# ATSAMA5D35 register map
Vendor: Microchip Technology; Series: SAMA5D3; File version: 0
Registers are 32-bit, read-write, reset 0x0 unless marked. A register's access mark holds for its fields unless they carry their own. Offsets are from the block's base; [hi:lo] are bit positions; lines under a group give offsets from that group; {n}, {i} and the like mark numbered series; 'fields as' and 'values as' point back to an identical list.

## TC0 — Timer Counter
Base 0xF0010000; register names take the prefix TC_
Same registers: TC1 0xF8014000
{0x0+0x40*i} TC_CHANNEL[{i}] (i=0..2) group
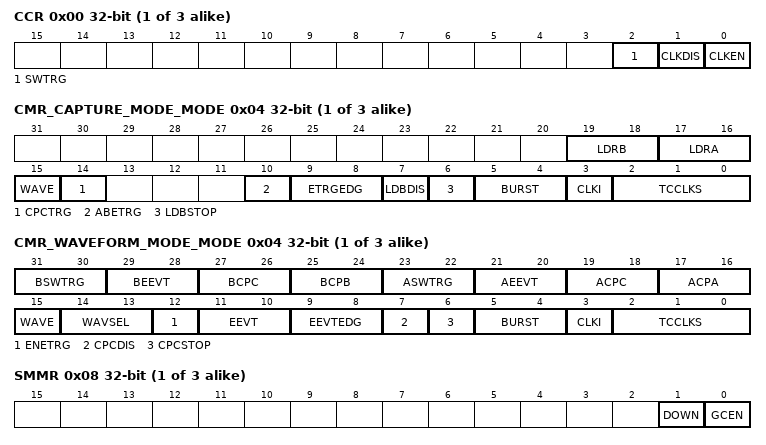
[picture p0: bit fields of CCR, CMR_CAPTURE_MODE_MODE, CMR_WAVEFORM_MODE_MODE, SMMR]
  0x00 CCR wo — Channel Control Register
    [2] SWTRG — Software Trigger Command
    [1] CLKDIS — Counter Clock Disable Command
    [0] CLKEN — Counter Clock Enable Command
  0x04 CMR_CAPTURE_MODE_MODE — Channel Mode Register
    [19:18] LDRB — RB Loading Edge Selection
      0=NONE; 1=RISING (Rising edge of TIOA); 2=FALLING (Falling edge of TIOA); 3=EDGE (Each edge of TIOA)
    [17:16] LDRA — RA Loading Edge Selection
      values as LDRB
    [15] WAVE — Waveform Mode
    [14] CPCTRG — RC Compare Trigger Enable
    [10] ABETRG — TIOA or TIOB External Trigger Selection
    [9:8] ETRGEDG — External Trigger Edge Selection
      0=NONE (The clock is not gated by an external signal.); 1=RISING (Rising edge); 2=FALLING (Falling edge); 3=EDGE (Each edge)
    [7] LDBDIS — Counter Clock Disable with RB Loading
    [6] LDBSTOP — Counter Clock Stopped with RB Loading
    [5:4] BURST — Burst Signal Selection
      0=NONE (The clock is not gated by an external signal.); 1=XC0 (XC0 is ANDed with the selected clock.); 2=XC1 (XC1 is ANDed with the selected clock.); 3=XC2 (XC2 is ANDed with the selected clock.)
    [3] CLKI — Clock Invert
    [2:0] TCCLKS — Clock Selection
      0=TIMER_CLOCK1 (Clock selected: internal div2 clock signal (from PMC)); 1=TIMER_CLOCK2 (Clock selected: internal div8 clock signal (from PMC)); 2=TIMER_CLOCK3 (Clock selected: internal div32 clock signal (from PMC)); 3=TIMER_CLOCK4 (Clock selected: internal div128 clock signal (from PMC)); 4=TIMER_CLOCK5 (Clock selected: internal slow_clock clock signal (from PMC)); 5=XC0 (Clock selected: XC0); 6=XC1 (Clock selected: XC1); 7=XC2 (Clock selected: XC2)
  0x04 CMR_WAVEFORM_MODE_MODE (alternate view of CMR_CAPTURE_MODE_MODE) — Channel Mode Register
    [31:30] BSWTRG — Software Trigger Effect on TIOB
      0=NONE; 1=SET; 2=CLEAR; 3=TOGGLE
    [29:28] BEEVT — External Event Effect on TIOB
      0=NONE; 1=SET; 2=CLEAR; 3=TOGGLE
    [27:26] BCPC — RC Compare Effect on TIOB
      0=NONE; 1=SET; 2=CLEAR; 3=TOGGLE
    [25:24] BCPB — RB Compare Effect on TIOB
      0=NONE; 1=SET; 2=CLEAR; 3=TOGGLE
    [23:22] ASWTRG — Software Trigger Effect on TIOA
      0=NONE; 1=SET; 2=CLEAR; 3=TOGGLE
    [21:20] AEEVT — External Event Effect on TIOA
      0=NONE; 1=SET; 2=CLEAR; 3=TOGGLE
    [19:18] ACPC — RC Compare Effect on TIOA
      0=NONE; 1=SET; 2=CLEAR; 3=TOGGLE
    [17:16] ACPA — RA Compare Effect on TIOA
      0=NONE; 1=SET; 2=CLEAR; 3=TOGGLE
    [15] WAVE — Waveform Mode
    [14:13] WAVSEL — Waveform Selection
      0=UP (UP mode without automatic trigger on RC Compare); 1=UPDOWN (UPDOWN mode without automatic trigger on RC Compare); 2=UP_RC (UP mode with automatic trigger on RC Compare); 3=UPDOWN_RC (UPDOWN mode with automatic trigger on RC Compare)
    [12] ENETRG — External Event Trigger Enable
    [11:10] EEVT — External Event Selection
      0=TIOB; 1=XC0; 2=XC1; 3=XC2
    [9:8] EEVTEDG — External Event Edge Selection
      0=NONE; 1=RISING (Rising edge); 2=FALLING (Falling edge); 3=EDGE (Each edge)
    [7] CPCDIS — Counter Clock Disable with RC Compare
    [6] CPCSTOP — Counter Clock Stopped with RC Compare
    [5:4] BURST — Burst Signal Selection
      values as TC_CHANNEL[0].CMR_CAPTURE_MODE_MODE.BURST
    [3] CLKI — Clock Invert
    [2:0] TCCLKS — Clock Selection
      values as TC_CHANNEL[0].CMR_CAPTURE_MODE_MODE.TCCLKS
  0x08 SMMR — Stepper Motor Mode Register
    [1] DOWN — Down Count
    [0] GCEN — Gray Count Enable
  0x10 CV ro — Counter Value
  0x14 RA — Register A
  0x18 RB — Register B
  0x1C RC — Register C
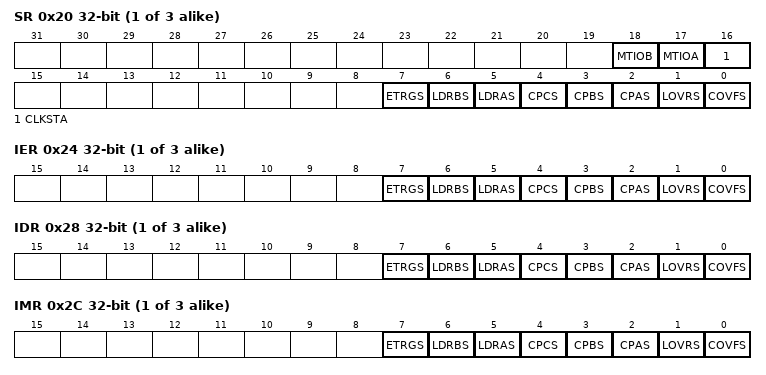
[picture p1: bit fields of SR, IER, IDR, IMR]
  0x20 SR ro — Status Register
    [18] MTIOB — TIOB Mirror
    [17] MTIOA — TIOA Mirror
    [16] CLKSTA — Clock Enabling Status
    [7] ETRGS — External Trigger Status (cleared on read)
    [6] LDRBS — RB Loading Status (cleared on read)
    [5] LDRAS — RA Loading Status (cleared on read)
    [4] CPCS — RC Compare Status (cleared on read)
    [3] CPBS — RB Compare Status (cleared on read)
    [2] CPAS — RA Compare Status (cleared on read)
    [1] LOVRS — Load Overrun Status (cleared on read)
    [0] COVFS — Counter Overflow Status (cleared on read)
  0x24 IER wo — Interrupt Enable Register
    [7] ETRGS — External Trigger
    [6] LDRBS — RB Loading
    [5] LDRAS — RA Loading
    [4] CPCS — RC Compare
    [3] CPBS — RB Compare
    [2] CPAS — RA Compare
    [1] LOVRS — Load Overrun
    [0] COVFS — Counter Overflow
  0x28 IDR wo — Interrupt Disable Register
    fields as TC_CHANNEL[0].IER
  0x2C IMR ro — Interrupt Mask Register
    fields as TC_CHANNEL[0].IER
0xC0 BCR wo — Block Control Register
  [0] SYNC — Synchro Command
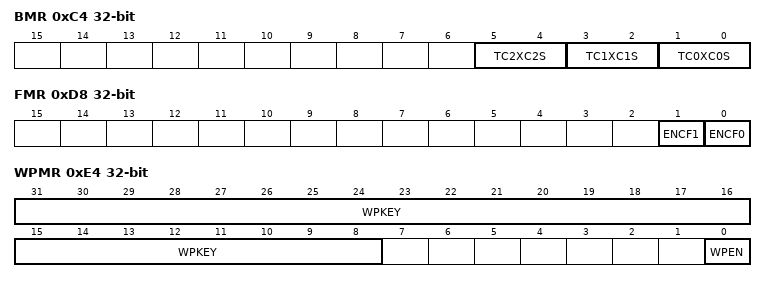
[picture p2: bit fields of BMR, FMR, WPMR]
0xC4 BMR — Block Mode Register
  [5:4] TC2XC2S — External Clock Signal 2 Selection
    0=TCLK2 (Signal connected to XC2: TCLK2); 2=TIOA0 (Signal connected to XC2: TIOA0); 3=TIOA1 (Signal connected to XC2: TIOA1)
  [3:2] TC1XC1S — External Clock Signal 1 Selection
    0=TCLK1 (Signal connected to XC1: TCLK1); 2=TIOA0 (Signal connected to XC1: TIOA0); 3=TIOA2 (Signal connected to XC1: TIOA2)
  [1:0] TC0XC0S — External Clock Signal 0 Selection
    0=TCLK0 (Signal connected to XC0: TCLK0); 2=TIOA1 (Signal connected to XC0: TIOA1); 3=TIOA2 (Signal connected to XC0: TIOA2)
0xD8 FMR — Fault Mode Register
  [1] ENCF1 — Enable Compare Fault Channel 1
  [0] ENCF0 — Enable Compare Fault Channel 0
0xE4 WPMR — Write Protection Mode Register
  [31:8] WPKEY — Write Protection Key
    0x54494D=PASSWD (Writing any other value in this field aborts the write operation of the WPEN bit.Always reads as 0.)
  [0] WPEN — Write Protection Enable

## Notices in the file
Copyright (c) 2026 Microchip Technology Inc.
SPDX-License-Identifier: Apache-2.0
Licensed under the Apache License, Version 2.0 (the "License");
you may not use this file except in compliance with the License.
You may obtain a copy of the License at
http://www.apache.org/licenses/LICENSE-2.0
Unless required by applicable law or agreed to in writing, software
distributed under the License is distributed on an "AS IS" BASIS,
WITHOUT WARRANTIES OR CONDITIONS OF ANY KIND, either express or implied.
See the License for the specific language governing permissions and
limitations under the License.
